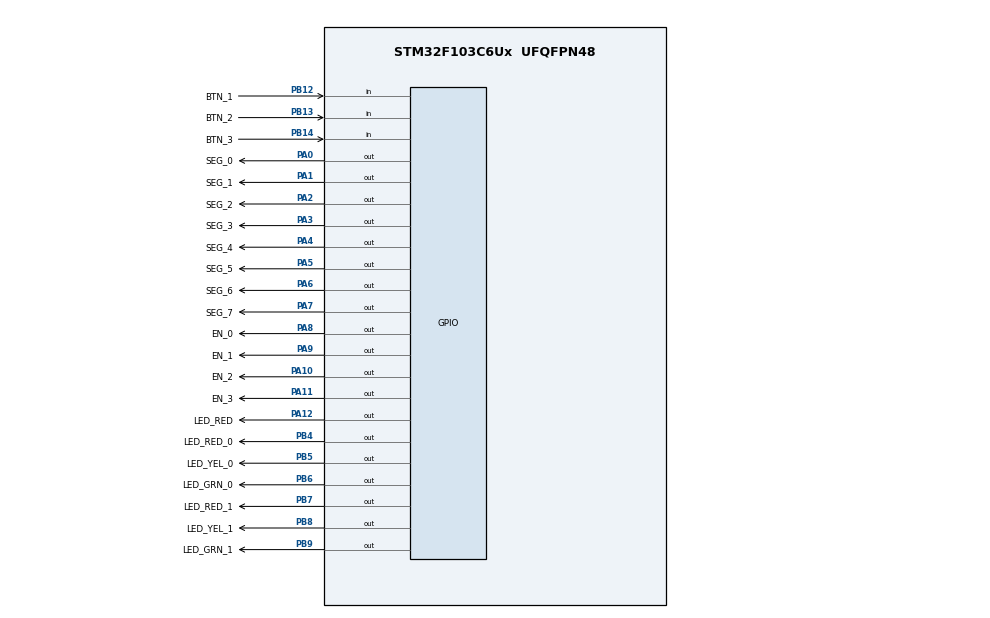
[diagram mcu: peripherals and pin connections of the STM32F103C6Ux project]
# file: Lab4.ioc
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Mcu.Family=STM32F1
Mcu.Name=STM32F103C6Ux
Mcu.Package=UFQFPN48
NVIC.PriorityGroup=NVIC_PRIORITYGROUP_4
NVIC.TIM2_IRQn=true\:0\:0\:false\:false\:true\:true\:true\:true
PA0-WKUP.GPIO_Label=SEG_0
PA0-WKUP.Signal=GPIO_Output
PA1.GPIO_Label=SEG_1
PA1.PinState=GPIO_PIN_RESET
PA1.Signal=GPIO_Output
PA10.GPIO_Label=EN_2
PA10.PinState=GPIO_PIN_SET
PA10.Signal=GPIO_Output
PA11.GPIO_Label=EN_3
PA11.PinState=GPIO_PIN_SET
PA11.Signal=GPIO_Output
PA12.GPIO_Label=LED_RED
PA12.Signal=GPIO_Output
PA13.Mode=Serial_Wire
PA13.Signal=SYS_JTMS-SWDIO
PA14.Mode=Serial_Wire
PA14.Signal=SYS_JTCK-SWCLK
PA2.GPIO_Label=SEG_2
PA2.PinState=GPIO_PIN_RESET
PA2.Signal=GPIO_Output
PA3.GPIO_Label=SEG_3
PA3.PinState=GPIO_PIN_RESET
PA3.Signal=GPIO_Output
PA4.GPIO_Label=SEG_4
PA4.PinState=GPIO_PIN_RESET
PA4.Signal=GPIO_Output
PA5.GPIO_Label=SEG_5
PA5.PinState=GPIO_PIN_RESET
PA5.Signal=GPIO_Output
PA6.GPIO_Label=SEG_6
PA6.PinState=GPIO_PIN_RESET
PA6.Signal=GPIO_Output
PA7.GPIO_Label=SEG_7
PA7.PinState=GPIO_PIN_RESET
PA7.Signal=GPIO_Output
PA8.GPIO_Label=EN_0
PA8.PinState=GPIO_PIN_SET
PA8.Signal=GPIO_Output
PA9.GPIO_Label=EN_1
PA9.PinState=GPIO_PIN_SET
PA9.Signal=GPIO_Output
PB12.GPIO_Label=BTN_1
PB12.GPIO_PuPd=GPIO_NOPULL
PB12.Signal=GPIO_Input
PB13.GPIO_Label=BTN_2
PB13.Signal=GPIO_Input
PB14.GPIO_Label=BTN_3
PB14.Signal=GPIO_Input
PB4.GPIO_Label=LED_RED_0
PB4.Signal=GPIO_Output
PB5.GPIO_Label=LED_YEL_0
PB5.Signal=GPIO_Output
PB6.GPIO_Label=LED_GRN_0
PB6.Signal=GPIO_Output
PB7.GPIO_Label=LED_RED_1
PB7.Signal=GPIO_Output
PB8.GPIO_Label=LED_YEL_1
PB8.Signal=GPIO_Output
PB9.GPIO_Label=LED_GRN_1
PB9.Signal=GPIO_Output
ProjectManager.HeapSize=0x200
ProjectManager.StackSize=0x400
ProjectManager.TargetToolchain=STM32CubeIDE
RCC.APB1Freq_Value=8000000
RCC.APB2Freq_Value=8000000
TIM2.Period=9
TIM2.Prescaler=799
VP_TIM2_VS_ClockSourceINT.Mode=Internal
board=custom

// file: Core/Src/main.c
/* USER CODE BEGIN Header */
/**
  ******************************************************************************
  * @file           : main.c
  * @brief          : Main program body
  ******************************************************************************
  * @attention
  *
  * Copyright (c) 2025 STMicroelectronics.
  * All rights reserved.
  *
  * This software is licensed under terms that can be found in the LICENSE file
  * in the root directory of this software component.
  * If no LICENSE file comes with this software, it is provided AS-IS.
  *
  ******************************************************************************
  */
/* USER CODE END Header */
#include "main.h"

/* USER CODE BEGIN Includes */
#include "global.h"
/* USER CODE END Includes */

TIM_HandleTypeDef htim2;

void SystemClock_Config(void);
static void MX_GPIO_Init(void);
static void MX_TIM2_Init(void);
/* USER CODE BEGIN PFP */
void HAL_TIM_PeriodElapsedCallback(TIM_HandleTypeDef *htim);
/* USER CODE END PFP */

int main(void)
{

  /* MCU Configuration--------------------------------------------------------*/

  /* Reset of all peripherals, Initializes the Flash interface and the Systick. */
  HAL_Init();

  /* USER CODE BEGIN Init */
  SCH_Init();
//  SCH_Add_Task(timerRun, 0, 1);
  SCH_Add_Task(statusLED, 0 , 1000);
  SCH_Add_Task(get3ButtonInput, 0, 10);
  SCH_Add_Task(fsm_traffic_light, 0, 10);           // FSM chính
  SCH_Add_Task(task_update_traffic_light, 0, 1);  // LED giao thông
  SCH_Add_Task(task_countdown, 0 , 1000);
  SCH_Add_Task(task_update_7segment, 0, 1);       // Quét 7-seg
  /* USER CODE END Init */

  /* Configure the system clock */
  SystemClock_Config();

  /* Initialize all configured peripherals */
  MX_GPIO_Init();
  MX_TIM2_Init();
  /* USER CODE BEGIN 2 */
  HAL_TIM_Base_Start_IT(&htim2);
  /* USER CODE END 2 */

  /* Infinite loop */
  /* USER CODE BEGIN WHILE */
  while (1)
  {
	  SCH_Dispatch_Tasks();
    /* USER CODE END WHILE */

  }
}

void SystemClock_Config(void)
{
  RCC_OscInitTypeDef RCC_OscInitStruct = {0};
  RCC_ClkInitTypeDef RCC_ClkInitStruct = {0};

  /** Initializes the RCC Oscillators according to the specified parameters
  * in the RCC_OscInitTypeDef structure.
  */
  RCC_OscInitStruct.OscillatorType = RCC_OSCILLATORTYPE_HSI;
  RCC_OscInitStruct.HSIState = RCC_HSI_ON;
  RCC_OscInitStruct.HSICalibrationValue = RCC_HSICALIBRATION_DEFAULT;
  RCC_OscInitStruct.PLL.PLLState = RCC_PLL_NONE;
  if (HAL_RCC_OscConfig(&RCC_OscInitStruct) != HAL_OK)
  {
    Error_Handler();
  }

  /** Initializes the CPU, AHB and APB buses clocks
  */
  RCC_ClkInitStruct.ClockType = RCC_CLOCKTYPE_HCLK|RCC_CLOCKTYPE_SYSCLK
                              |RCC_CLOCKTYPE_PCLK1|RCC_CLOCKTYPE_PCLK2;
  RCC_ClkInitStruct.SYSCLKSource = RCC_SYSCLKSOURCE_HSI;
  RCC_ClkInitStruct.AHBCLKDivider = RCC_SYSCLK_DIV1;
  RCC_ClkInitStruct.APB1CLKDivider = RCC_HCLK_DIV1;
  RCC_ClkInitStruct.APB2CLKDivider = RCC_HCLK_DIV1;

  if (HAL_RCC_ClockConfig(&RCC_ClkInitStruct, FLASH_LATENCY_0) != HAL_OK)
  {
    Error_Handler();
  }
}

static void MX_TIM2_Init(void)
{

  TIM_ClockConfigTypeDef sClockSourceConfig = {0};
  TIM_MasterConfigTypeDef sMasterConfig = {0};

  htim2.Instance = TIM2;
  htim2.Init.Prescaler = 799;
  htim2.Init.CounterMode = TIM_COUNTERMODE_UP;
  htim2.Init.Period = 9;
  htim2.Init.ClockDivision = TIM_CLOCKDIVISION_DIV1;
  htim2.Init.AutoReloadPreload = TIM_AUTORELOAD_PRELOAD_DISABLE;
  if (HAL_TIM_Base_Init(&htim2) != HAL_OK)
  {
    Error_Handler();
  }
  sClockSourceConfig.ClockSource = TIM_CLOCKSOURCE_INTERNAL;
  if (HAL_TIM_ConfigClockSource(&htim2, &sClockSourceConfig) != HAL_OK)
  {
    Error_Handler();
  }
  sMasterConfig.MasterOutputTrigger = TIM_TRGO_RESET;
  sMasterConfig.MasterSlaveMode = TIM_MASTERSLAVEMODE_DISABLE;
  if (HAL_TIMEx_MasterConfigSynchronization(&htim2, &sMasterConfig) != HAL_OK)
  {
    Error_Handler();
  }

}

static void MX_GPIO_Init(void)
{
  GPIO_InitTypeDef GPIO_InitStruct = {0};

  /* GPIO Ports Clock Enable */
  __HAL_RCC_GPIOA_CLK_ENABLE();
  __HAL_RCC_GPIOB_CLK_ENABLE();

  /*Configure GPIO pin Output Level */
  HAL_GPIO_WritePin(GPIOA, SEG_0_Pin|SEG_1_Pin|SEG_2_Pin|SEG_3_Pin
                          |SEG_4_Pin|SEG_5_Pin|SEG_6_Pin|SEG_7_Pin
                          |LED_RED_Pin, GPIO_PIN_RESET);

  /*Configure GPIO pin Output Level */
  HAL_GPIO_WritePin(GPIOA, EN_0_Pin|EN_1_Pin|EN_2_Pin|EN_3_Pin, GPIO_PIN_SET);

  /*Configure GPIO pin Output Level */
  HAL_GPIO_WritePin(GPIOB, LED_RED_0_Pin|LED_YEL_0_Pin|LED_GRN_0_Pin|LED_RED_1_Pin
                          |LED_YEL_1_Pin|LED_GRN_1_Pin, GPIO_PIN_RESET);

  /*Configure GPIO pins : SEG_0_Pin SEG_1_Pin SEG_2_Pin SEG_3_Pin
                           SEG_4_Pin SEG_5_Pin SEG_6_Pin SEG_7_Pin
                           EN_0_Pin EN_1_Pin EN_2_Pin EN_3_Pin
                           LED_RED_Pin */
  GPIO_InitStruct.Pin = SEG_0_Pin|SEG_1_Pin|SEG_2_Pin|SEG_3_Pin
                          |SEG_4_Pin|SEG_5_Pin|SEG_6_Pin|SEG_7_Pin
                          |EN_0_Pin|EN_1_Pin|EN_2_Pin|EN_3_Pin
                          |LED_RED_Pin;
  GPIO_InitStruct.Mode = GPIO_MODE_OUTPUT_PP;
  GPIO_InitStruct.Pull = GPIO_NOPULL;
  GPIO_InitStruct.Speed = GPIO_SPEED_FREQ_LOW;
  HAL_GPIO_Init(GPIOA, &GPIO_InitStruct);

  /*Configure GPIO pins : BTN_1_Pin BTN_2_Pin BTN_3_Pin */
  GPIO_InitStruct.Pin = BTN_1_Pin|BTN_2_Pin|BTN_3_Pin;
  GPIO_InitStruct.Mode = GPIO_MODE_INPUT;
  GPIO_InitStruct.Pull = GPIO_NOPULL;
  HAL_GPIO_Init(GPIOB, &GPIO_InitStruct);

  /*Configure GPIO pins : LED_RED_0_Pin LED_YEL_0_Pin LED_GRN_0_Pin LED_RED_1_Pin
                           LED_YEL_1_Pin LED_GRN_1_Pin */
  GPIO_InitStruct.Pin = LED_RED_0_Pin|LED_YEL_0_Pin|LED_GRN_0_Pin|LED_RED_1_Pin
                          |LED_YEL_1_Pin|LED_GRN_1_Pin;
  GPIO_InitStruct.Mode = GPIO_MODE_OUTPUT_PP;
  GPIO_InitStruct.Pull = GPIO_NOPULL;
  GPIO_InitStruct.Speed = GPIO_SPEED_FREQ_LOW;
  HAL_GPIO_Init(GPIOB, &GPIO_InitStruct);

}

/* USER CODE BEGIN 4 */
void HAL_TIM_PeriodElapsedCallback(TIM_HandleTypeDef *htim)
{
   SCH_Update();
}
/* USER CODE END 4 */

void Error_Handler(void)
{
  __disable_irq();
  while (1)
  {
  }
}
